# SF32LB52x register map
File version: 1.0
CPU: CM33 r0p1, little endian, MPU, FPU, 3 interrupt priority bits
Registers are 32-bit, read-write, reset 0x0 unless marked. A register's access mark holds for its fields unless they carry their own. Offsets are from the block's base; [hi:lo] are bit positions; {n}, {i} and the like mark numbered series; 'fields as' and 'values as' point back to an identical list.

## EPIC
Base 0x50007000
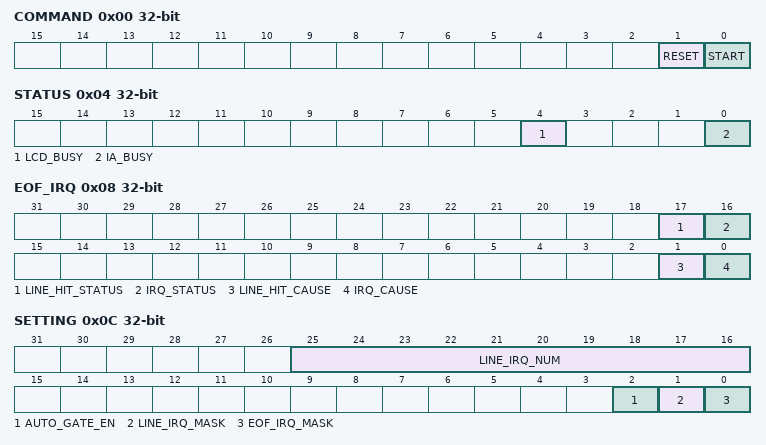
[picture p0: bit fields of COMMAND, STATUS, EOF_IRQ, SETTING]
0x00 COMMAND
  [1] RESET — 1: reset the whole graphics 0: release the reset
  [0] START — write 1 to trigger the lcd interface block
0x04 STATUS
  [4] LCD_BUSY — LCD controll busy flag
  [0] IA_BUSY — Graphics accelerator busy flag
0x08 EOF_IRQ
  [17] LINE_HIT_STATUS — raw status of line hit interrupt
  [16] IRQ_STATUS — raw status of end of frame interrupt
  [1] LINE_HIT_CAUSE — line hit interrupt, can be masked by LINE_IRQ_MASK
  [0] IRQ_CAUSE — end of frame interrupt, can be masked by EOF_IRQ_MASK
0x0C SETTING
  [25:16] LINE_IRQ_NUM — canvas line hit interrupt line number
  [2] AUTO_GATE_EN — auto clock gating enable
  [1] LINE_IRQ_MASK — canvas line hit interrupt mask, 0: mask the interrupt
  [0] EOF_IRQ_MASK — end of frame interrupt mask, 0: mask the interrupt
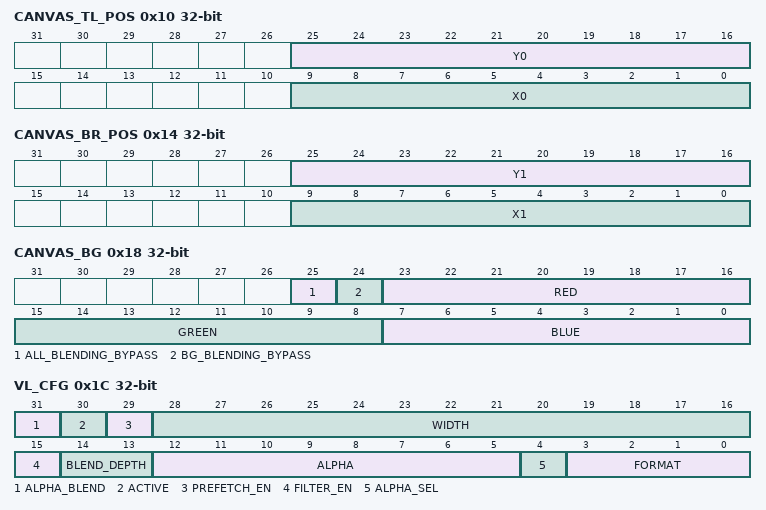
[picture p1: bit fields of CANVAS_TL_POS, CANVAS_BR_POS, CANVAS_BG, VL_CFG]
0x10 CANVAS_TL_POS — Top-Left pixel coordinate
  [25:16] Y0, [9:0] X0
0x14 CANVAS_BR_POS — Bottom-Right pixel coordinate
  [25:16] Y1, [9:0] X1
0x18 CANVAS_BG — Background color
  [25] ALL_BLENDING_BYPASS — if this bit is set, epic is in pure dma mode. No blending operation.
  [24] BG_BLENDING_BYPASS — if this bit is set, the layer is not blending with background. The alpha value will be reserved to output.
  [23:16] RED — Red color
  [15:8] GREEN — green color
  [7:0] BLUE — blue color
0x1C VL_CFG
  [31] ALPHA_BLEND — set 1 to enable alpha blending mode. Use layer alpha as blending factor for image with Alpha. Alpha_out = Layer_alpha * Image_alpha
  [30] ACTIVE — layer active flag
  [29] PREFETCH_EN — preload 64 bytes extra data when reading pixel from memory
  [28:16] WIDTH — source image width(including padding), unit is bytes
  [15] FILTER_EN — layer color filter enable
  [14:13] BLEND_DEPTH — video layer blending depth
  [12:5] ALPHA — layer alpha value
  [4] ALPHA_SEL — alpha selection 1'b0: select alpha according to image format 1'b1: select layer alpha
  [3:0] FORMAT — video layer input format 4'h0: RGB565 4'h1: RGB888 4'h2: ARGB8888 4'h3: ARGB8565 4'h4: A8 4'h5: A4 4'h6: L8 4'h7: A2
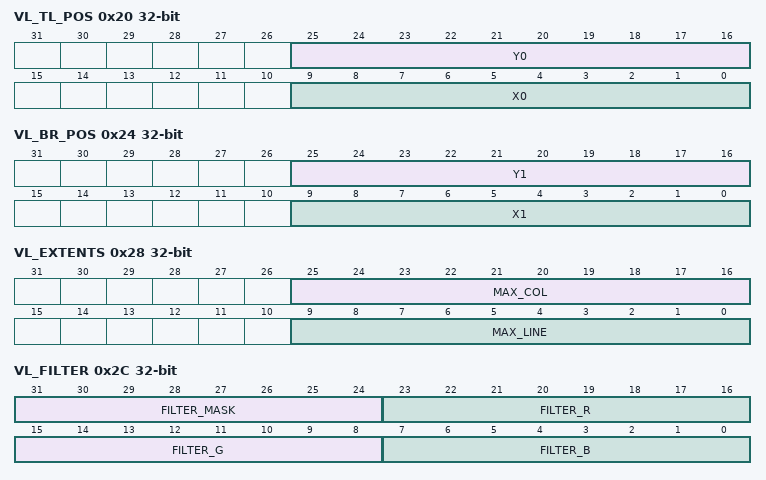
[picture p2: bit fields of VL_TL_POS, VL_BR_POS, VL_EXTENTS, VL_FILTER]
0x20 VL_TL_POS
  [25:16] Y0 — Coordingate Y-value
  [9:0] X0 — Coordinate X-value
0x24 VL_BR_POS
  [25:16] Y1 — Coordingate Y-value
  [9:0] X1 — Coordinate X-value
0x28 VL_EXTENTS
  [25:16] MAX_COL — number of pixels of each line of source image(not including padding)
  [9:0] MAX_LINE — number of pixels of each column of source image(not including padding)
0x2C VL_FILTER
  [31:24] FILTER_MASK — layer color filter mask
  [23:16] FILTER_R — filter r color
  [15:8] FILTER_G — filter g color
  [7:0] FILTER_B — filter b color
0x30 VL_SRC
  [31:0] ADDR — source image RGB data address[31:0]. For RGB565 format, address should be aligned to halfword. For ARGB8888 format, address should be aligned to word.
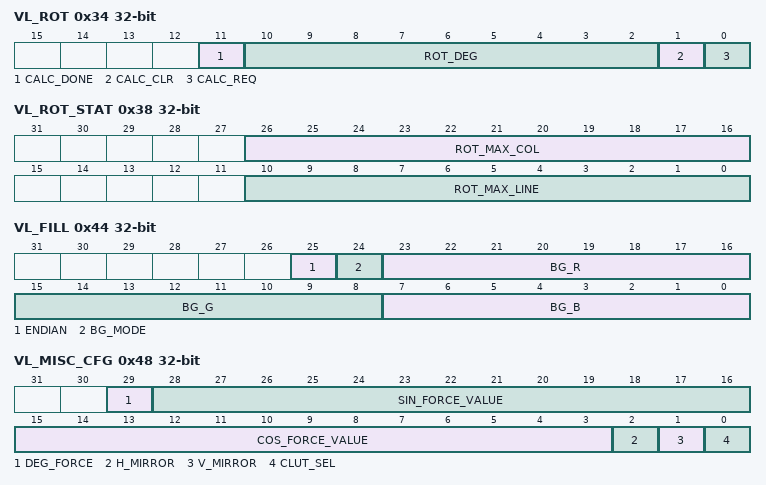
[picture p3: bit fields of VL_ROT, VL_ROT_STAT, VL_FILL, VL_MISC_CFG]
0x34 VL_ROT
  [11] CALC_DONE — calculation done indicator
  [10:2] ROT_DEG — rotation degree, rotation is clockwise.
  [1] CALC_CLR — rot_max_col and rot_max_line calculation clear request. Write 1 to clear the result.
  [0] CALC_REQ — rot_max_col and rot_max_line calculation request. Write 1 to trigger the calculation.
0x38 VL_ROT_STAT
  [26:16] ROT_MAX_COL — max column of rotated image
  [10:0] ROT_MAX_LINE — max line of rotated image
0x3C VL_SCALE_RATIO_H
  [25:0] XPITCH — x-axis rescaling ration, 10.16 fixed point number, XPITCH lt MAX_COL/(X1-X0)
0x40 VL_SCALE_RATIO_V
  [25:0] YPITCH — y-axis rescaling ratio, 10.16 fixed point number, YPITCH lt MAX_LINE/(Y1-Y0)
0x44 VL_FILL
  [25] ENDIAN — input 565 data format endian 0: {R[4:0], G[5:3], G[2:0], B[4:0]} 1: {G[2:0], R[4:0], B[4:0], G[5:3]}
  [24] BG_MODE — Not used.
  [23:16] BG_R — background r color
  [15:8] BG_G — background g color
  [7:0] BG_B — background b color
0x48 VL_MISC_CFG
  [29] DEG_FORCE — force epic use external sin and cos value, quadrant is still calculated from ROT_DEG.
  [28:16] SIN_FORCE_VALUE — external absolute value of sin. U13.12 format.
  [15:3] COS_FORCE_VALUE — external absolute value of cos. U13.12 format.
  [2] H_MIRROR — horizontal mirror enable
  [1] V_MIRROR — vertical mirror enable
  [0] CLUT_SEL — VL CLUT select: 1'h1: select pallette1 1'h0: select pallette0
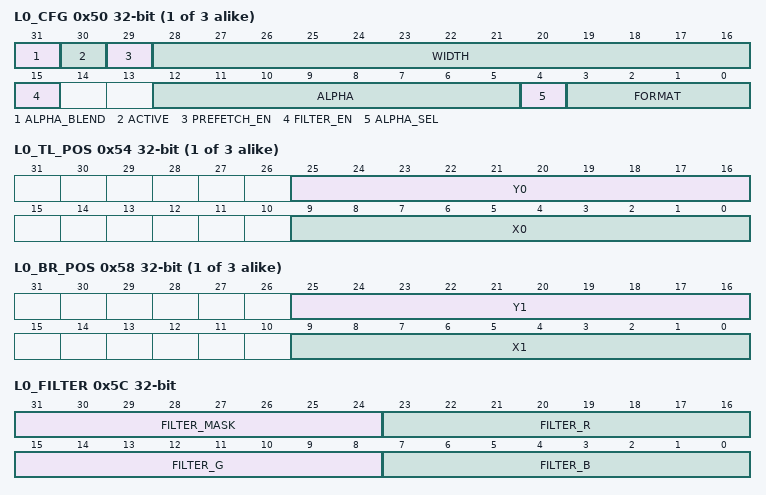
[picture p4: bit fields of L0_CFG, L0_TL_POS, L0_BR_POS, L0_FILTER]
{0x50+0x20*i} L{i}_CFG (i=0..2)
  [31] ALPHA_BLEND — set 1 to enable alpha blending mode. Use layer alpha as blending factor for image with Alpha. Alpha_out = Layer_alpha * Image_alpha
  [30] ACTIVE — layer active flag
  [29] PREFETCH_EN — preload 64 bytes extra data when reading pixel from memory
  [28:16] WIDTH — source image width(including padding), unit is bytes
  [15] FILTER_EN — layer color filter enable
  [12:5] ALPHA — layer alpha value
  [4] ALPHA_SEL — alpha selection 1'b0: select alpha according to image format 1'b1: select layer alpha
  [3:0] FORMAT — layer input format 4'h0: RGB565 4'h1: RGB888 4'h2: ARGB8888 4'h3: ARGB8565 4'h4: A8 4'h5: A4 4'h6: L8 4'h7: A2
{0x54+0x20*i} L{i}_TL_POS (i=0..2)
  [25:16] Y0 — Coordingate Y-value
  [9:0] X0 — Coordinate X-value
{0x58+0x20*i} L{i}_BR_POS (i=0..2)
  [25:16] Y1 — Coordingate Y-value
  [9:0] X1 — Coordinate X-value
0x5C L0_FILTER
  fields as VL_FILTER
0x60 L0_SRC
  fields as VL_SRC
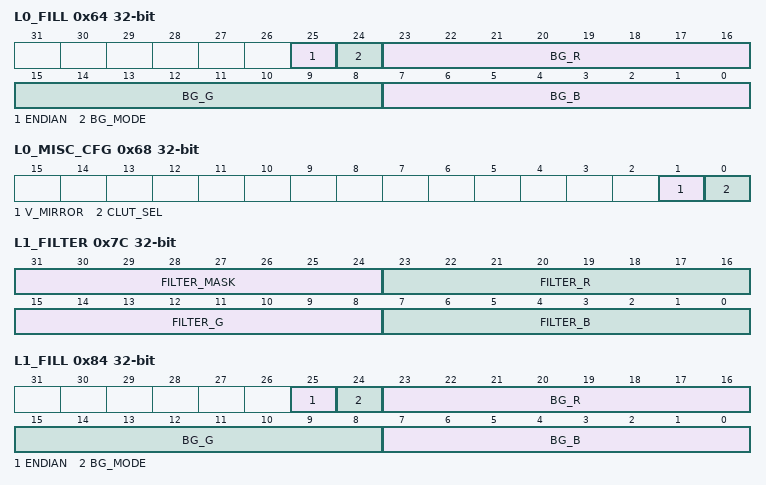
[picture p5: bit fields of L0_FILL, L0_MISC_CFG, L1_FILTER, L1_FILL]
0x64 L0_FILL
  fields as VL_FILL
0x68 L0_MISC_CFG
  [1] V_MIRROR — vertical mirror enable
  [0] CLUT_SEL — L0 CLUT select: 1'h1: select pallette1 1'h0: select pallette0
0x7C L1_FILTER
  fields as VL_FILTER
0x80 L1_SRC
  fields as VL_SRC
0x84 L1_FILL
  fields as VL_FILL
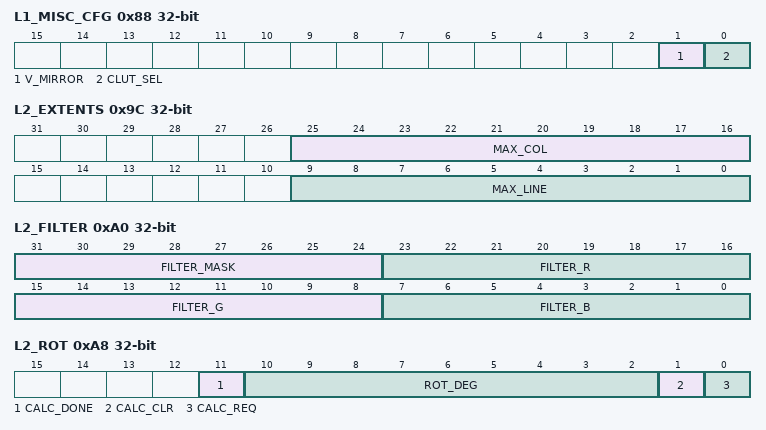
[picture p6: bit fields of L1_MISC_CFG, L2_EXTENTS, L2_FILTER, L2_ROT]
0x88 L1_MISC_CFG
  [1] V_MIRROR — vertical mirror enable
  [0] CLUT_SEL — L1 CLUT select: 1'h1: select pallette1 1'h0: select pallette0
0x9C L2_EXTENTS
  fields as VL_EXTENTS
0xA0 L2_FILTER
  fields as VL_FILTER
0xA4 L2_SRC
  fields as VL_SRC
0xA8 L2_ROT
  fields as VL_ROT
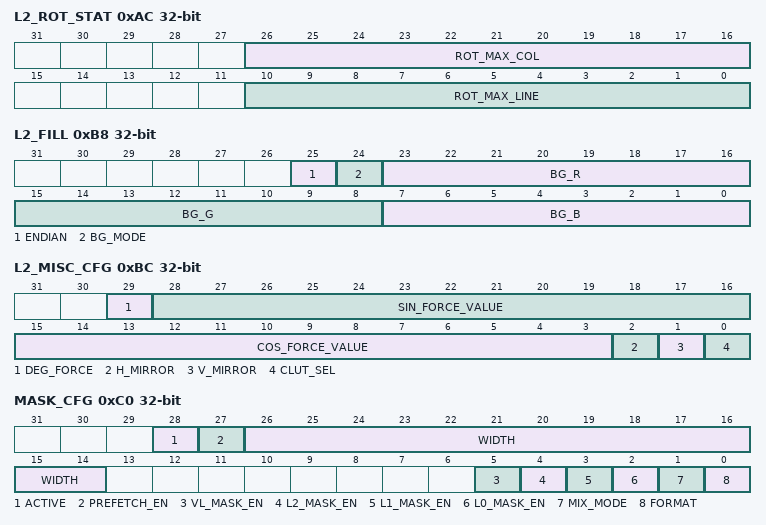
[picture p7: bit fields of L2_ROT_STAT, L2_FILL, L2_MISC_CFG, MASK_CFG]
0xAC L2_ROT_STAT
  fields as VL_ROT_STAT
0xB0 L2_SCALE_RATIO_H
  fields as VL_SCALE_RATIO_H
0xB4 L2_SCALE_RATIO_V
  fields as VL_SCALE_RATIO_V
0xB8 L2_FILL
  fields as VL_FILL
0xBC L2_MISC_CFG
  [29] DEG_FORCE — force epic use external sin and cos value, quadrant is still calculated from ROT_DEG.
  [28:16] SIN_FORCE_VALUE — external absolute value of sin. U13.12 format.
  [15:3] COS_FORCE_VALUE — external absolute value of cos. U13.12 format.
  [2] H_MIRROR — horizontal mirror enable
  [1] V_MIRROR — vertical mirror enable
  [0] CLUT_SEL — L2 CLUT select: 1'h1: select pallette1 1'h0: select pallette0
0xC0 MASK_CFG
  [28] ACTIVE — layer active flag
  [27] PREFETCH_EN — preload 64 bytes extra data when reading pixel from memory
  [26:14] WIDTH — source image width(including padding), unit is bytes
  [5] VL_MASK_EN — video layer mask enable
  [4] L2_MASK_EN — layer2 mask enable
  [3] L1_MASK_EN — layer1 mask enable
  [2] L0_MASK_EN — layer0 mask enable
  [1] MIX_MODE — mask mix mode 1'h0: mult mode 1'h1: overwrite mode
  [0] FORMAT — mask input format 1'h0: A8 1'h1: A4
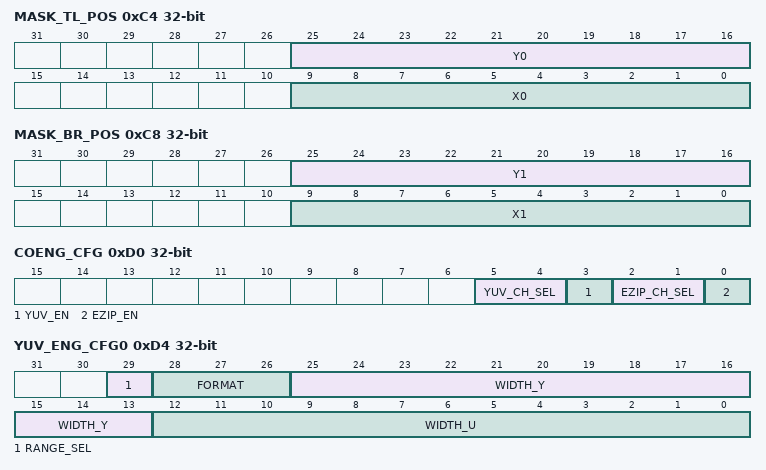
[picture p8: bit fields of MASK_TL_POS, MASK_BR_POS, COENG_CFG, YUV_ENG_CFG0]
0xC4 MASK_TL_POS
  [25:16] Y0 — Coordingate Y-value
  [9:0] X0 — Coordinate X-value
0xC8 MASK_BR_POS
  [25:16] Y1 — Coordingate Y-value
  [9:0] X1 — Coordinate X-value
0xCC MASK_SRC
  [31:0] ADDR — mask data address[31:0]. This is byte address, even for A4, this address is byte aligned.
0xD0 COENG_CFG
  [5:4] YUV_CH_SEL — yuv engine channel select
  [3] YUV_EN — yuv enable
  [2:1] EZIP_CH_SEL — ezip channel select
  [0] EZIP_EN — ezip enable
0xD4 YUV_ENG_CFG0
  [29] RANGE_SEL — yuv input range 1'h0: tv range 1'h1: pc range
  [28:26] FORMAT — yuv format
  [25:13] WIDTH_Y — yuv y vector line width, unit is bytes
  [12:0] WIDTH_U — yuv u vector line width, unit is bytes
0xD8 YUV_ENG_CFG1
  [12:0] WIDTH_V — yuv v vector line width, unit is bytes
0xDC Y_SRC
  [31:0] ADDR — y vector address
0xE0 U_SRC
  [31:0] ADDR — u vector address
0xE4 V_SRC
  [31:0] ADDR — v vector address
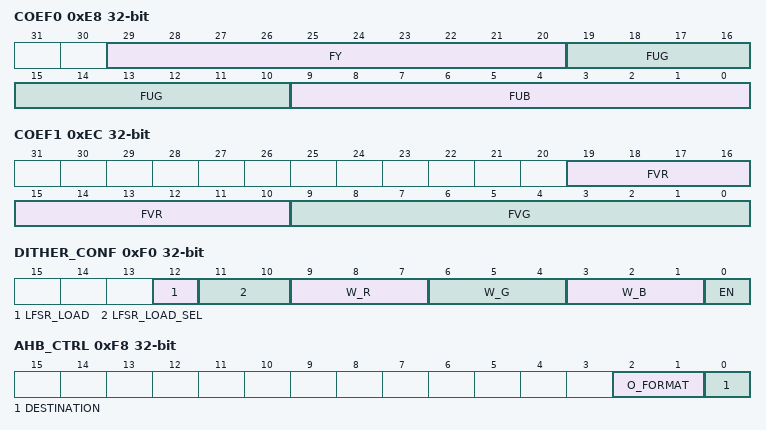
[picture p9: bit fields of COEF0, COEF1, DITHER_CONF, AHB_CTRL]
0xE8 COEF0
  [29:20] FY — YUV Fy coef
  [19:10] FUG — YUV Fug coef
  [9:0] FUB — YUV Fub coef
0xEC COEF1
  [19:10] FVR — YUV Fvr coef
  [9:0] FVG — YUV Fvg coef
0xF0 DITHER_CONF
  [12] LFSR_LOAD — load lfsr init value
  [11:10] LFSR_LOAD_SEL — select lfsr 0: none 1: red 2: green 3: blue
  [9:7] W_R — red dither width
  [6:4] W_G — green dither width
  [3:1] W_B — blue dither width
  [0] EN — dither enable
0xF4 DITHER_LFSR
  [31:0] INIT_VAL — lfsr init load value
0xF8 AHB_CTRL
  [2:1] O_FORMAT — AHB output format: 2'h0: RGB565 2'h1: RGB888 2'h2: ARGB8888 2'h3: ARGB8565
  [0] DESTINATION — The Data can be sent to two destinations: 2'b0: AHB RAM 2'b1: AHB LCD
0xFC AHB_MEM
  [31:0] ADDR — AHB RAM/AHB LCD target address
0x100 AHB_STRIDE
  [15:0] OFFSET
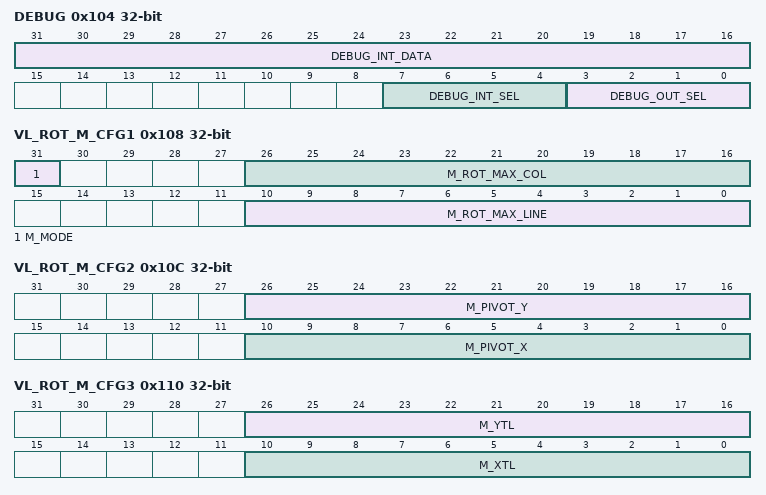
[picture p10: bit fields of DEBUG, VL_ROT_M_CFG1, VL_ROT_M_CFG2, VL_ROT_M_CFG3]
0x104 DEBUG
  [31:16] DEBUG_INT_DATA — 4'h0: RSVD 4'h1: OL0 debug info 4'h2: OL1 debug info 4'h3: OL2 debug info 4'h4: VL debug info1 4'h5: VL debug info2 4'h6: ROI debug out 4'h7: mem intfa debug out 4'h8: mem intfb debug out 4'h9: ahb ctrl debug out 4'ha: ROI XX 4'hb: ROI YY 4'hc: EPIC_EZIP debug out others: RSVD
  [7:4] DEBUG_INT_SEL
  [3:0] DEBUG_OUT_SEL
0x108 VL_ROT_M_CFG1
  [31] M_MODE — rotation mode setting 1'b0: auto mode 1'b1: manual mode
  [26:16] M_ROT_MAX_COL — manual mode rotation max column, unsigned value
  [10:0] M_ROT_MAX_LINE — manual mode rotation max line, unsigned value
0x10C VL_ROT_M_CFG2
  [26:16] M_PIVOT_Y — manual mode pivot y, signed value, -1023~1023, -1024 is not supported
  [10:0] M_PIVOT_X — manual mode pivot x, signed value, -1023~1023, -1024 is not supported
0x110 VL_ROT_M_CFG3
  [26:16] M_YTL — manual mode top left y cordinate, signed value, -1023~1023, -1024 is not supported
  [10:0] M_XTL — manual mode top left x cordinate, signed value, -1023~1023, -1024 is not supported
0x114 VL_SCALE_INIT_CFG1
  [25:0] X_VAL — x-axis scale initial value, 10.16 format
0x118 VL_SCALE_INIT_CFG2
  [25:0] Y_VAL — y-axis scale initial value, 10.16 format
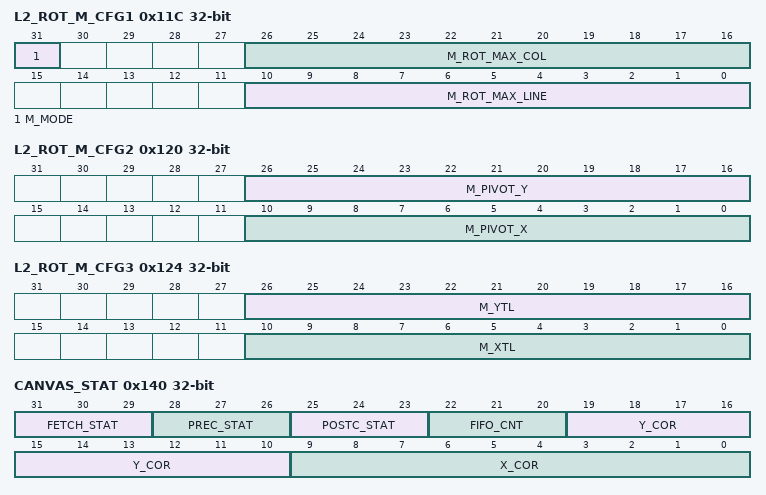
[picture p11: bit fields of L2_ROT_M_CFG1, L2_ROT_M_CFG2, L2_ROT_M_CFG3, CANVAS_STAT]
0x11C L2_ROT_M_CFG1
  fields as VL_ROT_M_CFG1
0x120 L2_ROT_M_CFG2
  fields as VL_ROT_M_CFG2
0x124 L2_ROT_M_CFG3
  fields as VL_ROT_M_CFG3
0x128 L2_SCALE_INIT_CFG1
  [25:0] X_VAL — x-axis scale initial value, 10.16 format
0x12C L2_SCALE_INIT_CFG2
  [25:0] Y_VAL — y-axis scale initial value, 10.16 format
0x130 PERF_CNT
  [31:0] VAL — epic performance counter
0x140 CANVAS_STAT
  [31:29] FETCH_STAT — fetch status
  [28:26] PREC_STAT — prec status
  [25:23] POSTC_STAT — postc_status
  [22:20] FIFO_CNT — pre calc fifo count
  [19:10] Y_COR — canvas y cordinate
  [9:0] X_COR — canvas x cordinate
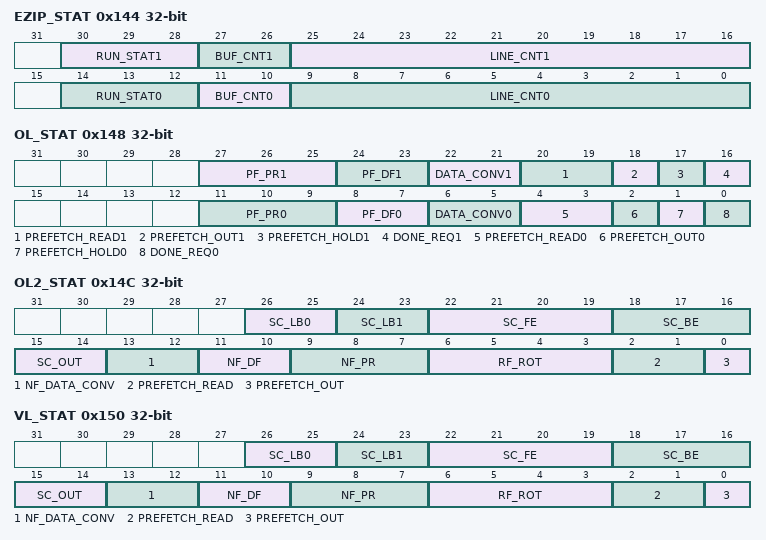
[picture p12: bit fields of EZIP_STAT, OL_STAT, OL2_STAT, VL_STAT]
0x144 EZIP_STAT
  [30:28] RUN_STAT1 — ezip engine 1 status
  [27:26] BUF_CNT1 — ezip engine 1 buffer count
  [25:16] LINE_CNT1 — ezip engine 1 line count
  [14:12] RUN_STAT0 — ezip engine 0 status
  [11:10] BUF_CNT0 — ezip engine 0 buffer count
  [9:0] LINE_CNT0 — ezip engine 0 line count
0x148 OL_STAT
  [27:25] PF_PR1, [24:23] PF_DF1, [22:21] DATA_CONV1, [20:19] PREFETCH_READ1, [18] PREFETCH_OUT1, [17] PREFETCH_HOLD1, [16] DONE_REQ1, [11:9] PF_PR0, [8:7] PF_DF0, [6:5] DATA_CONV0, [4:3] PREFETCH_READ0, [2] PREFETCH_OUT0, [1] PREFETCH_HOLD0, [0] DONE_REQ0
0x14C OL2_STAT
  [26:25] SC_LB0, [24:23] SC_LB1, [22:19] SC_FE, [18:16] SC_BE, [15:14] SC_OUT, [13:12] NF_DATA_CONV, [11:10] NF_DF, [9:7] NF_PR, [6:3] RF_ROT, [2:1] PREFETCH_READ, [0] PREFETCH_OUT
0x150 VL_STAT
  fields as OL2_STAT
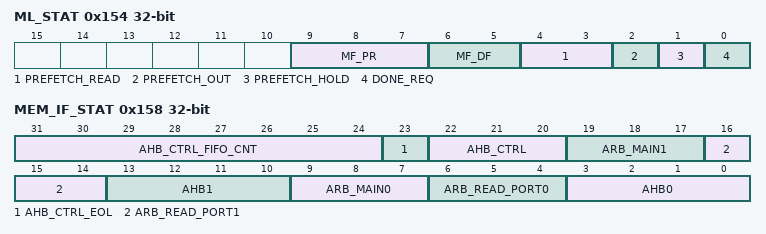
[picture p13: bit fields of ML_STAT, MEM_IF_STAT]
0x154 ML_STAT
  [9:7] MF_PR, [6:5] MF_DF, [4:3] PREFETCH_READ, [2] PREFETCH_OUT, [1] PREFETCH_HOLD, [0] DONE_REQ
0x158 MEM_IF_STAT
  [31:24] AHB_CTRL_FIFO_CNT, [23] AHB_CTRL_EOL, [22:20] AHB_CTRL, [19:17] ARB_MAIN1, [16:14] ARB_READ_PORT1, [13:10] AHB1, [9:7] ARB_MAIN0, [6:4] ARB_READ_PORT0, [3:0] AHB0
